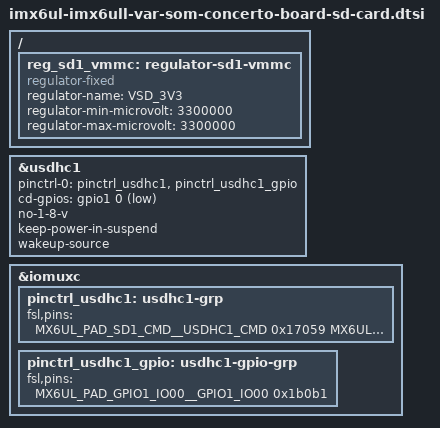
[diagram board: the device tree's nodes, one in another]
// SPDX-License-Identifier: GPL-2.0+
/*
 * Copyright (C) 2026 Variscite Ltd. - https://www.variscite.com
 */

/ {
	reg_sd1_vmmc: regulator-sd1-vmmc {
		compatible = "regulator-fixed";
		regulator-name = "VSD_3V3";
		regulator-min-microvolt = <3300000>;
		regulator-max-microvolt = <3300000>;
	};
};

&usdhc1 {
	pinctrl-names = "default";
	pinctrl-0 = <&pinctrl_usdhc1>, <&pinctrl_usdhc1_gpio>;
	cd-gpios = <&gpio1 0 GPIO_ACTIVE_LOW>;
	no-1-8-v;
	keep-power-in-suspend;
	wakeup-source;
	status = "okay";
};

&iomuxc {
	pinctrl_usdhc1: usdhc1-grp {
		fsl,pins = <
			MX6UL_PAD_SD1_CMD__USDHC1_CMD		0x17059
			MX6UL_PAD_SD1_CLK__USDHC1_CLK		0x17059
			MX6UL_PAD_SD1_DATA0__USDHC1_DATA0	0x17059
			MX6UL_PAD_SD1_DATA1__USDHC1_DATA1	0x17059
			MX6UL_PAD_SD1_DATA2__USDHC1_DATA2	0x17059
			MX6UL_PAD_SD1_DATA3__USDHC1_DATA3	0x17059
		>;
	};

	pinctrl_usdhc1_gpio: usdhc1-gpio-grp {
		fsl,pins = <
			MX6UL_PAD_GPIO1_IO00__GPIO1_IO00	0x1b0b1 /* CD */
		>;
	};
};
